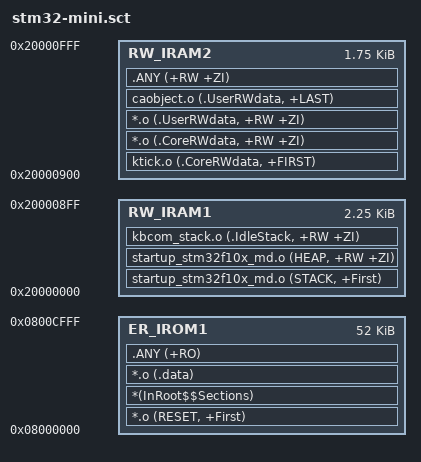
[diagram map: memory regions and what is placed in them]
;
;    This is open source software.
;    Learning and research can be unrestricted to  modification, use and dissemination.
;    If you need for commercial purposes, you should get the author's permission.
;
;    Configuration:
;     System global core stack                  NO
;     The local core stack of general task      YES
;     The loacl core stack of kernel task       YES
;     The local user stack of general task      NO
;     Hardware supported task switch IRQ        YES
;     Hardware supported double stack           NO
;
;    date           author          notes
;    2015-06-25     JiangYong       new file

LR_IROM1 0x08000000 0x0000D000  {    ; load region size_region
  ER_IROM1 0x08000000 0x0000D000  {  ; load address = execution address
   *.o (RESET, +First)
   *(InRoot$$Sections)
   *.o (.data)
   .ANY (+RO)
  }
  RW_IRAM1 0x20000000 0x00000900  {  ; RW data
   startup_stm32f10x_md.o (STACK, +First)
   startup_stm32f10x_md.o (HEAP, +RW +ZI)
   kbcom_stack.o (.IdleStack, +RW +ZI)
;   kbstm32_stack.o (.CoreStack, +RW +ZI)
  }
  RW_IRAM2 0x20000900 0x00000700  {  ; RW data
   ktick.o (.CoreRWdata, +FIRST)
   *.o (.CoreRWdata, +RW +ZI)
   *.o (.UserRWdata, +RW +ZI)
   caobject.o (.UserRWdata, +LAST)
   .ANY (+RW +ZI)
  }
}

